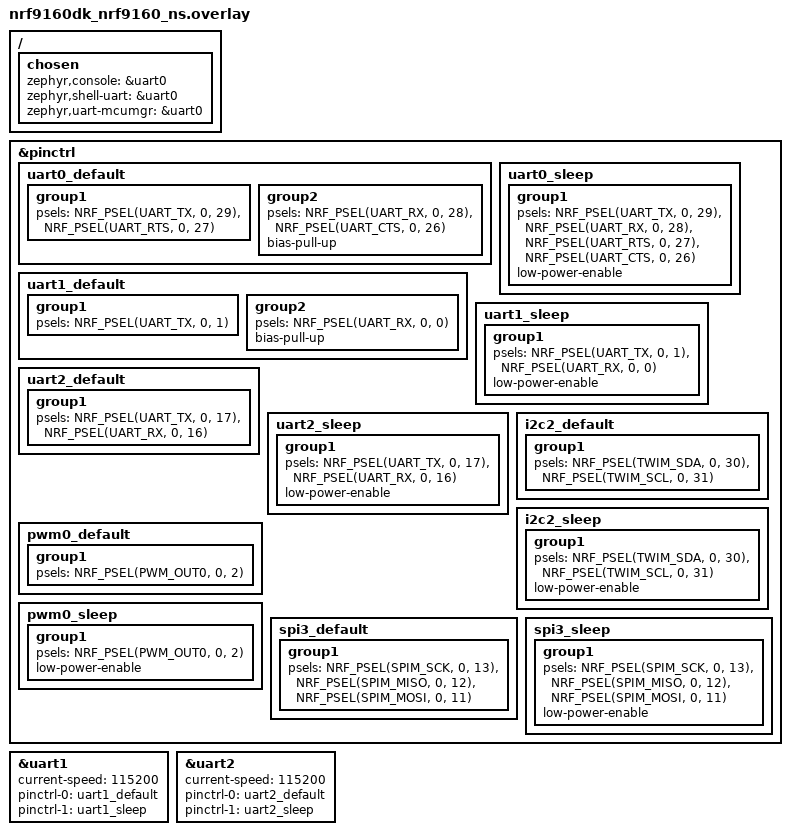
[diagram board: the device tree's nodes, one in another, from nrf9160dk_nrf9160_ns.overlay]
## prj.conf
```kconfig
# Logging
CONFIG_PRINTK=y
CONFIG_LOG=y
CONFIG_LOG_DEFAULT_LEVEL=4

CONFIG_UART_ASYNC_API=y

# So we can use k_malloc
CONFIG_HEAP_MEM_POOL_SIZE=16384


# disable logging from the secure application to enable use of UART1
# https://developer.nordicsemi.com/nRF_Connect_SDK/doc/latest/nrf/security/tfm.html
CONFIG_BUILD_WITH_TFM=y
CONFIG_TFM_LOG_LEVEL_SILENCE=y
CONFIG_TFM_SECURE_UART=n
CONFIG_TFM_SECURE_UART1=n


# CONFIG_TFM_SECURE_UART=n
# CONFIG_NRF_UARTE1_SECURE=n
CONFIG_NRF_UARTE2_SECURE=n


# CONFIG_NRF_MODEM_LIB=y
```

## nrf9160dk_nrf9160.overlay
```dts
 &pinctrl {
	uart0_default: uart0_default {
		group1 {
			psels = <NRF_PSEL(UART_TX, 0, 29)>,
				<NRF_PSEL(UART_RTS, 0, 27)>;
		};
		group2 {
			psels = <NRF_PSEL(UART_RX, 0, 28)>,
				<NRF_PSEL(UART_CTS, 0, 26)>;
			bias-pull-up;
		};
	};

	uart0_sleep: uart0_sleep {
		group1 {
			psels = <NRF_PSEL(UART_TX, 0, 29)>,
				<NRF_PSEL(UART_RX, 0, 28)>,
				<NRF_PSEL(UART_RTS, 0, 27)>,
				<NRF_PSEL(UART_CTS, 0, 26)>;
			low-power-enable;
		};
	};

	uart1_default: uart1_default {
		group1 {
			psels = <NRF_PSEL(UART_TX, 0, 1)>;
				// <NRF_PSEL(UART_RTS, 0, 14)>;
		};
		group2 {
			psels = <NRF_PSEL(UART_RX, 0, 0)>;
				// <NRF_PSEL(UART_CTS, 0, 15)>;
			bias-pull-up;
		};
	};

	uart1_sleep: uart1_sleep {
		group1 {
			psels = <NRF_PSEL(UART_TX, 0, 1)>,
				<NRF_PSEL(UART_RX, 0, 0)>;
				// <NRF_PSEL(UART_RTS, 0, 14)>,
				// <NRF_PSEL(UART_CTS, 0, 15)>;
			low-power-enable;
		};
	};

	uart2_default: uart2_default {
		group1 {
			psels = <NRF_PSEL(UART_TX, 0, 16)>,
				<NRF_PSEL(UART_RX, 0, 15)>;
		};
	};

	uart2_sleep: uart2_sleep {
		group1 {
			psels = <NRF_PSEL(UART_TX, 0, 16)>,
				<NRF_PSEL(UART_RX, 0, 15)>;
			low-power-enable;
		};
	};

	i2c2_default: i2c2_default {
		group1 {
			psels = <NRF_PSEL(TWIM_SDA, 0, 30)>,
				<NRF_PSEL(TWIM_SCL, 0, 31)>;
		};
	};

	i2c2_sleep: i2c2_sleep {
		group1 {
			psels = <NRF_PSEL(TWIM_SDA, 0, 30)>,
				<NRF_PSEL(TWIM_SCL, 0, 31)>;
			low-power-enable;
		};
	};

	pwm0_default: pwm0_default {
		group1 {
			psels = <NRF_PSEL(PWM_OUT0, 0, 2)>;
		};
	};

	pwm0_sleep: pwm0_sleep {
		group1 {
			psels = <NRF_PSEL(PWM_OUT0, 0, 2)>;
			low-power-enable;
		};
	};

	spi3_default: spi3_default {
		group1 {
			psels = <NRF_PSEL(SPIM_SCK, 0, 13)>,
				<NRF_PSEL(SPIM_MISO, 0, 12)>,
				<NRF_PSEL(SPIM_MOSI, 0, 11)>;
		};
	};

	spi3_sleep: spi3_sleep {
		group1 {
			psels = <NRF_PSEL(SPIM_SCK, 0, 13)>,
				<NRF_PSEL(SPIM_MISO, 0, 12)>,
				<NRF_PSEL(SPIM_MOSI, 0, 11)>;
			low-power-enable;
		};
	};
};


&uart2 {
    status = "okay";
	current-speed = <115200>;
	pinctrl-0 = <&uart2_default>;
	pinctrl-1 = <&uart2_sleep>;
	pinctrl-names = "default", "sleep";
};
```

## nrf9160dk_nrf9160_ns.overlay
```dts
/ {
    chosen {
        zephyr,console = &uart0;
		zephyr,shell-uart = &uart0;
		zephyr,uart-mcumgr = &uart0;
    };
};

&pinctrl {
	uart0_default: uart0_default {
		group1 {
			psels = <NRF_PSEL(UART_TX, 0, 29)>,
				<NRF_PSEL(UART_RTS, 0, 27)>;
		};
		group2 {
			psels = <NRF_PSEL(UART_RX, 0, 28)>,
				<NRF_PSEL(UART_CTS, 0, 26)>;
			bias-pull-up;
		};
	};

	uart0_sleep: uart0_sleep {
		group1 {
			psels = <NRF_PSEL(UART_TX, 0, 29)>,
				<NRF_PSEL(UART_RX, 0, 28)>,
				<NRF_PSEL(UART_RTS, 0, 27)>,
				<NRF_PSEL(UART_CTS, 0, 26)>;
			low-power-enable;
		};
	};

	uart1_default: uart1_default {
		group1 {
			psels = <NRF_PSEL(UART_TX, 0, 1)>;
				// <NRF_PSEL(UART_RTS, 0, 14)>;
		};
		group2 {
			psels = <NRF_PSEL(UART_RX, 0, 0)>;
				// <NRF_PSEL(UART_CTS, 0, 15)>;
			bias-pull-up;
		};
	};

	uart1_sleep: uart1_sleep {
		group1 {
			psels = <NRF_PSEL(UART_TX, 0, 1)>,
				<NRF_PSEL(UART_RX, 0, 0)>;
				// <NRF_PSEL(UART_RTS, 0, 14)>,
				// <NRF_PSEL(UART_CTS, 0, 15)>;
			low-power-enable;
		};
	};

	uart2_default: uart2_default {
		group1 {
			psels = <NRF_PSEL(UART_TX, 0, 17)>,
				<NRF_PSEL(UART_RX, 0, 16)>;
		};
	};

	uart2_sleep: uart2_sleep {
		group1 {
			psels = <NRF_PSEL(UART_TX, 0, 17)>,
				<NRF_PSEL(UART_RX, 0, 16)>;
			low-power-enable;
		};
	};

	i2c2_default: i2c2_default {
		group1 {
			psels = <NRF_PSEL(TWIM_SDA, 0, 30)>,
				<NRF_PSEL(TWIM_SCL, 0, 31)>;
		};
	};

	i2c2_sleep: i2c2_sleep {
		group1 {
			psels = <NRF_PSEL(TWIM_SDA, 0, 30)>,
				<NRF_PSEL(TWIM_SCL, 0, 31)>;
			low-power-enable;
		};
	};

	pwm0_default: pwm0_default {
		group1 {
			psels = <NRF_PSEL(PWM_OUT0, 0, 2)>;
		};
	};

	pwm0_sleep: pwm0_sleep {
		group1 {
			psels = <NRF_PSEL(PWM_OUT0, 0, 2)>;
			low-power-enable;
		};
	};

	spi3_default: spi3_default {
		group1 {
			psels = <NRF_PSEL(SPIM_SCK, 0, 13)>,
				<NRF_PSEL(SPIM_MISO, 0, 12)>,
				<NRF_PSEL(SPIM_MOSI, 0, 11)>;
		};
	};

	spi3_sleep: spi3_sleep {
		group1 {
			psels = <NRF_PSEL(SPIM_SCK, 0, 13)>,
				<NRF_PSEL(SPIM_MISO, 0, 12)>,
				<NRF_PSEL(SPIM_MOSI, 0, 11)>;
			low-power-enable;
		};
	};
};


&uart1 {
    // status = "disabled";

	status = "okay";
	current-speed = <115200>;
	pinctrl-0 = <&uart1_default>;
	pinctrl-1 = <&uart1_sleep>;
	pinctrl-names = "default", "sleep";
};


&uart2 {
    status = "okay";
	current-speed = <115200>;
	pinctrl-0 = <&uart2_default>;
	pinctrl-1 = <&uart2_sleep>;
	pinctrl-names = "default", "sleep";
};
```

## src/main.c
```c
/*
 * THIS IS NOW BEING USED TO TEST UART RECEIVING
 */

#include <zephyr/kernel.h>
#include <zephyr/drivers/gpio.h>
#include <zephyr/drivers/i2c.h>
#include <zephyr/sys/printk.h>
#include <zephyr/drivers/uart.h>

#define SLEEP_TIME_MS   1000

#define UART uart1  // uart1: TX = P0.01, RX = P0.00.    TO BE USED FOR UART DEBUGGING
// #define UART uart2  // uart2: TX = P0.16, RX = P0.15.    TO BE USED FOR UART COMMS WITH nRF9160

const struct device *uart_dev = DEVICE_DT_GET(DT_NODELABEL(UART));

#define BUFF_SIZE 99  // IMPORTANT: RX and TX buffers must be the same size. This is bc UART_RX_RDY event only occurs when RX buffer is full.
static uint8_t* rx_buf;  // A buffer to store incoming UART data

#define MAGIC_NUMBER 77  // Used to confirm that incoming data is valid



static void uart_cb(const struct device *dev, struct uart_event *evt, void *user_data)
{

	switch (evt->type) {
	
	case UART_TX_DONE:
		// do something
		break;

	case UART_TX_ABORTED:
		// do something
		break;
		
	case UART_RX_RDY:
		printk("evt->data.rx.len: %d\n", evt->data.rx.len);
		// printk("	evt->data.rx.offset: %d\n", evt->data.rx.offset);

		// Sometimes, on boot, trash data is received, so this prevents us from trying to parse the trash data
		if (evt->data.rx.buf[evt->data.rx.offset] != MAGIC_NUMBER) {
			printk("Received data that did not start with the magic number. Ignoring it.\n");
			break;
		}
		if (evt->data.rx.len != BUFF_SIZE) {
			printk("Received data not correct length. Ignoring it.\n");
			break;
		}
		
		printk("data received: ");
		for (int i=0; i < evt->data.rx.len; i++) {
			printk("%02X ", evt->data.rx.buf[evt->data.rx.offset + i]);
		}
		printk("\n");
		break;

	case UART_RX_BUF_REQUEST:
		// printk("UART_RX_BUF_REQUEST\n");
		rx_buf = k_malloc(BUFF_SIZE * sizeof(uint8_t));
		if (rx_buf) {
			uart_rx_buf_rsp(uart_dev, rx_buf, BUFF_SIZE);
		} else {
			printk("WARNING: Not able to allocate UART receive buffer");
		}
		break;

	case UART_RX_BUF_RELEASED:
		// printk("UART_RX_BUF_RELEASED\n");
		k_free(rx_buf);
		break;
		
	case UART_RX_DISABLED:
		printk("UART_RX_DISABLED\n");
		uart_rx_enable(uart_dev, rx_buf, BUFF_SIZE, SYS_FOREVER_US);
		break;

	case UART_RX_STOPPED:
		printk("UART_RX_STOPPED\n");
		break;
		
	default:
		break;
	}
}


int main(void)
{
	k_msleep(1000);
	printk("Starting Program..\n");

	int ret;

	if (!device_is_ready(uart_dev)) {
		printk("uart not ready. returning.\n");
		return -1;
	}

	ret = uart_callback_set(uart_dev, uart_cb, NULL);
	if (ret) {
		return ret;
	}

	k_msleep(1000);
	ret = uart_rx_enable(uart_dev, rx_buf, BUFF_SIZE, SYS_FOREVER_US);
	if (ret) {
		printk("uart_rx_enable faild with ret=%d\n", ret);
		return ret;
	}

	static char tx_buf[100];
	for (int i=0; i<100; i++) {
		tx_buf[i] = 17;
	}

	int ctr = 0;
	while (1) {

		printk("Looping... %d\n", ctr);
		ctr++;

		ret = uart_tx(uart_dev, tx_buf, BUFF_SIZE, SYS_FOREVER_US);
		if (ret) {
			printk("uart_tx errored: %d.\n", ret);
		}

		k_msleep(SLEEP_TIME_MS);

	}
	return 0;
}
```
